# STM32U031 register map
File version: 1.0
CPU: CM0+ r0p1, little endian, MPU, no FPU, 4 interrupt priority bits
Registers are 32-bit, read-write, reset 0x0 unless marked. A register's access mark holds for its fields unless they carry their own. Offsets are from the block's base; [hi:lo] are bit positions.

## OPAMP — OPAMP address block description
Base 0x40007800
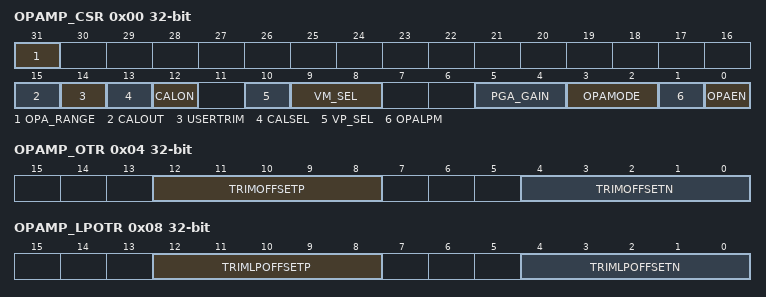
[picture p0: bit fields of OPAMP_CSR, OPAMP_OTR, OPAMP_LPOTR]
0x00 OPAMP_CSR access per field — OPAMP control/status register
  [31] OPA_RANGE rw — Operational amplifier power supply range for stability All AOP must be in power down to allow AOP-RANGE bit write. It applies to all AOP embedded in the product.
  [15] CALOUT ro — Operational amplifier calibration output During calibration mode offset is trimmed when this signal toggle.
  [14] USERTRIM rw — allows to switch from factory AOP offset trimmed values to AOP offset user trimmed values This bit is active for both mode normal and low-power.
  [13] CALSEL rw — Calibration selection
  [12] CALON rw — Calibration mode enabled
  [10] VP_SEL rw — Non inverted input selection
  [9:8] VM_SEL rw — Inverting input selection These bits are used only when OPAMODE = 00, 01 or 10. 1x: Inverting input not externally connected. These configurations are valid only when OPAMODE = 10 (PGA mode)
  [5:4] PGA_GAIN rw — Operational amplifier Programmable amplifier gain value
  [3:2] OPAMODE rw — Operational amplifier PGA mode
  [1] OPALPM rw — Operational amplifier Low Power Mode The operational amplifier must be disable to change this configuration.
  [0] OPAEN rw — Operational amplifier Enable
0x04 OPAMP_OTR (reset mask 0xFFFF0000) — OPAMP offset trimming register in normal mode
  [12:8] TRIMOFFSETP — Trim for PMOS differential pairs
  [4:0] TRIMOFFSETN — Trim for NMOS differential pairs
0x08 OPAMP_LPOTR (reset mask 0xFFFF0000) — OPAMP offset trimming register in low-power mode
  [12:8] TRIMLPOFFSETP — Low-power mode trim for PMOS differential pairs
  [4:0] TRIMLPOFFSETN — Low-power mode trim for NMOS differential pairs

## VREFBUF — VREFBUF address block description
Base 0x40010030
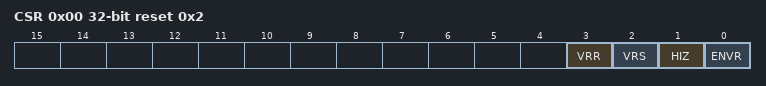
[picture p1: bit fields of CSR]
0x00 CSR access per field reset 0x2 — VREFBUF control and status register
  [3] VRR ro — Voltage reference buffer ready
  [2] VRS rw — Voltage reference scale This bit selects the value generated by the voltage reference buffer.
  [1] HIZ rw — High impedance mode This bit controls the analog switch to connect or not the V<sub>REF+</sub> pin. Refer to Table172: VREF buffer modes for the mode descriptions depending on ENVR bit configuration.
  [0] ENVR rw — Voltage reference buffer mode enable This bit is used to enable the voltage reference buffer mode.
0x04 CCR (reset mask 0xFFFFFF00) — VREFBUF calibration control register
  [5:0] TRIM

## WWDG — WWDG address block description
Base 0x40002C00
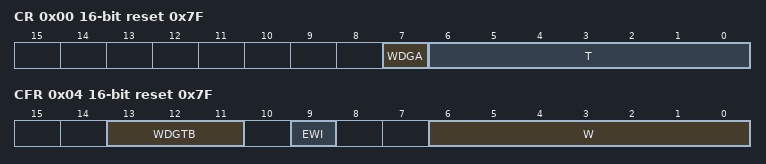
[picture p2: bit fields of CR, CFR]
0x00 CR 16-bit reset 0x7F — WWDG control register
  [7] WDGA — Activation bit This bit is set by software and only cleared by hardware after a reset. When WDGA=1, the watchdog can generate a reset.
    0=Disabled (Watchdog disabled); 1=Enabled (Watchdog enabled)
  [6:0] T — 7-bit counter (MSB to LSB) These bits contain the value of the watchdog counter, decremented every (4096 x 2<sup>WDGTB[2:0]</sup>) PCLK cycles. A reset is produced when it is decremented from 0x40 to 0x3F (T6 becomes cleared).
0x04 CFR 16-bit access not given reset 0x7F — WWDG configuration register
  [13:11] WDGTB — Timer base The timebase of the prescaler can be modified as follows:
    0=Div1 (Counter clock (PCLK1 div 4096) div 1); 1=Div2 (Counter clock (PCLK1 div 4096) div 2); 2=Div4 (Counter clock (PCLK1 div 4096) div 4); 3=Div8 (Counter clock (PCLK1 div 4096) div 8); 4=Div16 (Counter clock (PCLK1 div 4096) div 16); 5=Div32 (Counter clock (PCLK1 div 4096) div 32); 6=Div64 (Counter clock (PCLK1 div 4096) div 64); 7=Div128 (Counter clock (PCLK1 div 4096) div 128)
  [9] EWI rw — Early wake-up interrupt enable Set by software and cleared by hardware after a reset. When set, an interrupt occurs whenever the counter reaches the value 0x40.
    on write: 1=Enable (interrupt occurs whenever the counter reaches the value 0x40)
  [6:0] W rw — 7-bit window value These bits contain the window value to be compared with the down-counter.
0x08 SR 16-bit — WWDG status register
  [0] EWIF write-0-clears — Early wake-up interrupt flag This bit is set by hardware when the counter has reached the value 0x40. It must be cleared by software by writing 0. Writing 1 has no effect. This bit is also set if the interrupt is not enabled.
    on read: 0=Finished (The EWI Interrupt Service Routine has been serviced); 1=Pending (The EWI Interrupt Service Routine has been triggered) | on write: 0=Finished (The EWI Interrupt Service Routine has been serviced)
